# V32F20x_CM33 register map
File version: 1.0.3
CPU: CM33 r0p4, little endian, MPU, FPU, DSP, 3 interrupt priority bits, 8 SAU regions
Registers are 32-bit, read-write, reset 0x0 unless marked. A register's access mark holds for its fields unless they carry their own. Offsets are from the block's base; [hi:lo] are bit positions; {n}, {i} and the like mark numbered series.

## HFM — HFM Peripheral Interface
Base 0x21015000
0x00 DEVID ro reset 0xA0000B0C — HFM device ID register.
  [31:0] DEVID — HFM device ID value.
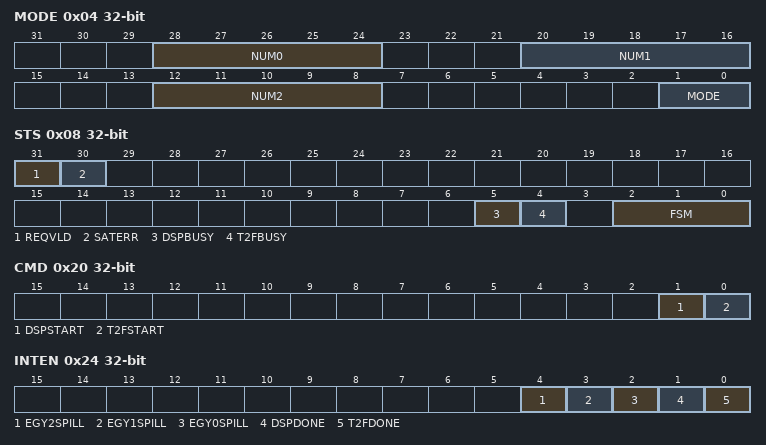
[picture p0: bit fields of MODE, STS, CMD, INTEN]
0x04 MODE — HFM mode configuration register.
  [28:24] NUM0 — Energy 0 bucket Harmonic number selection.
  [20:16] NUM1 — Energy 1 bucket Harmonic number selection.
  [12:8] NUM2 — Energy 2 bucket Harmonic number selection.
  [1:0] MODE — HFM mode configuration.
0x08 STS ro — HFM general status register.
  [31] REQVLD — Valid Request asserted.
  [30] SATERR — Saturation Error Occur.
  [5] DSPBUSY — The DSP is busy.
  [4] T2FBUSY — The T2F is busy.
  [2:0] FSM — FFT Transform state.
0x0C EXCHADDR — FFT exchange buffer base address register.
  [31:0] EXCHADDR — FFT calculation exchange buffer base address.
0x10 WAVEADDR — Waveform buffer base address register.
  [31:0] WAVEADDR — The source waveform FFT Result buffer base address
0x14 DSPINSTRADDR reset 0x80000 — DSP instructions base address register.
  [31:0] INSTRADDR — The DSP instruction buffer base address.
0x18 DSPEXCHADDR — DSP power result and exchange buffer base address register
  [31:0] DSPEXCHADDR — The DSP power value and exchange buffer base address
0x20 CMD — HFM command register.
  [1] DSPSTART — Start the DSP processing.
  [0] T2FSTART — Start run Bit. Write 1 to start the engine.
0x24 INTEN — HFM interrupt enable register.
  [4] EGY2SPILL — ENGY2 spill interrupt enable control.
  [3] EGY1SPILL — ENGY1 spill interrupt enable control.
  [2] EGY0SPILL — ENGY0 spill interrupt enable control.
  [1] DSPDONE — DSP process done interrupt enable control.
  [0] T2FDONE — T2F command done interrupt enable control.
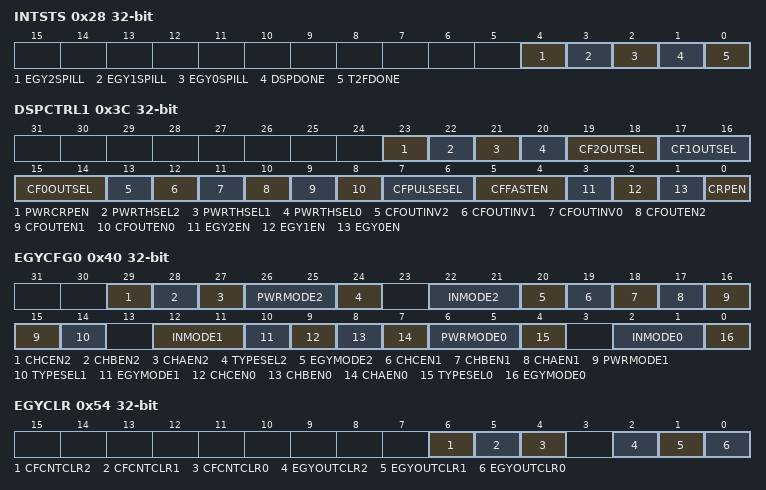
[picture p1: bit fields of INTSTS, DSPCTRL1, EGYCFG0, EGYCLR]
0x28 INTSTS — HFM interrupt status register.
  [4] EGY2SPILL — ENGY2 spill interrupt status.
  [3] EGY1SPILL — ENGY1 spill interrupt status.
  [2] EGY0SPILL — ENGY0 spill interrupt status.
  [1] DSPDONE — DSP process done interrupt status.
  [0] T2FDONE — T2F command done interrupt status.
{0x30+4i} EGY{i}CONST (i=0..2) — Energy x accumulation constant value register.
  [31:0] CONST — Energy bucket 0/1/2 accumulation constant value.
0x3C DSPCTRL1 — DSP control register 1.
  [23] PWRCRPEN — Power creeping enable control.
  [22] PWRTHSEL2 — Energy 2 power threshold value selection.
  [21] PWRTHSEL1 — Energy 1 power threshold value selection.
  [20] PWRTHSEL0 — Energy 0 power threshold value selection.
  [19:18] CF2OUTSEL — CF2 output energy bucket selection.
  [17:16] CF1OUTSEL — CF1 output energy bucket selection.
  [15:14] CF0OUTSEL — CF0 output energy bucket selection.
  [13] CFOUTINV2 — Polarity reversal of Energy Bucket 2.
  [12] CFOUTINV1 — Polarity reversal of Energy Bucket 1.
  [11] CFOUTINV0 — Polarity reversal of Energy Bucket 0.
  [10] CFOUTEN2 — CF2 output enable control.
  [9] CFOUTEN1 — CF1 output enable control.
  [8] CFOUTEN0 — CF0 output enable control.
  [7:6] CFPULSESEL — CF pulse period selection.
  [5:4] CFFASTEN — CF output frequency select through changing the threshold value
  [3] EGY2EN — Energy bucket 2 switch (including CF)
  [2] EGY1EN — Energy bucket 1 switch (including CF)
  [1] EGY0EN — Energy bucket 0 switch (including CF)
  [0] CRPEN — Energy bucket to prevent creeping switch control.
0x40 EGYCFG0 — Energy configuration register 0.
  [29] CHCEN2 — C channel of energy bucket 2 enable control.
  [28] CHBEN2 — B channel of energy bucket 2 enable control.
  [27] CHAEN2 — A channel of energy bucket 2 enable control.
  [26:25] PWRMODE2 — Energy bucket 2 power accumulation mode select
  [24] TYPESEL2 — Energy barrel 2 Power accumulation source selection
  [22:21] INMODE2 — Energy barrel 2 Accumulation source selection.
  [20] EGYMODE2 — Energy barrel 2 Energy accumulation mode selection
  [19] CHCEN1 — C channel of energy bucket 1 enable control.
  [18] CHBEN1 — B channel of energy bucket 1 enable control.
  [17] CHAEN1 — A channel of energy bucket 1 enable control.
  [16:15] PWRMODE1 — Energy bucket 1 power accumulation mode select
  [14] TYPESEL1 — Energy barrel 1 Power accumulation source selection
  [12:11] INMODE1 — Energy barrel 1 Accumulation source selection.
  [10] EGYMODE1 — Energy barrel 1 Energy accumulation mode selection
  [9] CHCEN0 — C channel of energy bucket 0 enable control.
  [8] CHBEN0 — B channel of energy bucket 0 enable control.
  [7] CHAEN0 — A channel of energy bucket 0 enable control.
  [6:5] PWRMODE0 — Energy bucket 0 power accumulation mode select
  [4] TYPESEL0 — Energy barrel 0 Power accumulation source selection
  [2:1] INMODE0 — Energy barrel 0 Accumulation source selection.
  [0] EGYMODE0 — Energy barrel 0 Energy accumulation mode selection
0x44 EGYPRCTH — Prevent potential threshold register.
  [31:0] PRCTH — Prevent creeping threshold
0x48 EGYPWRTH0 — Energy accumulation threshold 0 register.
  [31:0] PWRTH — Energy accumulation threshold 0.
0x4C EGYPWRTH1 — Energy accumulation threshold 1 register.
  [31:0] PWRTH — Energy accumulation threshold 1.
0x50 EGYCFDIVTH — CF frequency division coefficient register.
  [15:0] CFDIVTH — Energy bucket overflow counting threshold
0x54 EGYCLR — Energy value and CF count clear register.
  [6] CFCNTCLR2 — CF pulse count clear for energy bucket 2.
  [5] CFCNTCLR1 — CF pulse count clear for energy bucket 1.
  [4] CFCNTCLR0 — CF pulse count clear for energy bucket 0.
  [2] EGYOUTCLR2 — Cumulative energy value clear for energy bucket 2.
  [1] EGYOUTCLR1 — Cumulative energy value clear for energy bucket 1.
  [0] EGYOUTCLR0 — Cumulative energy value clear for energy bucket 0.
0x5C EGYCLKDIV — Power accumulation frequency register.
  [7:0] CLKDIV — Energy bucket accumulation cycle control.
{0x60+8i} EGY{i}OUTL ro (i=0..2) — Energy bucket x accumulation value low register.
  [31:0] OUTL — Accumulative value of energy bucket 0 1 2 low 32 bits
{0x64+8i} EGY{i}OUTH ro (i=0..2) — Energy bucket x accumulation value high register.
  [13:0] OUTH — Accumulative value of energy bucket 0 1 2 high 14 bits
{0x78+4i} EGY{i}CFCNT ro (i=0..2) — Energy bucket x CF counter register.
  [31:0] CFCNT — Energy bucket 0/1/2, CF pulse count value.
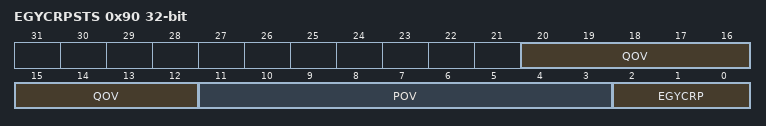
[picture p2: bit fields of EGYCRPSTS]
0x90 EGYCRPSTS ro — Energy creep status register.
  [20:12] QOV — Reactive power creeping status of each channel.
  [11:3] POV — Active power creeping status of each channel.
  [2:0] EGYCRP — The flag of creeping status.
0x94 PWROVTHH — Power creep over high threshold register.
  [31:0] THH — Power creep over high threshold.
0x98 PWROVTHL — Power creep over low threshold register.
  [31:0] THL — Power creep over low threshold.
0xA0 DSPCALICFGADDR reset 0x81700 — DSP PQ/RMS calibration configuration base address register
  [31:0] ADDR — The DSP calibration for PQ RMS base address default is NVR address
0x180 PW_P0_0 — The active power of phase A of energy bucket 0
  [31:0] P0_0 — Power value calculation by DSP
{0x184+0xC*i} PW_P{i}_1 (i=0..2) — The active power of phase B of energy bucket {i}
  [31:0] P{i}_1 — Power value calculation by DSP
{0x188+0xC*i} PW_P{i}_2 (i=0..2) — The active power of phase C of energy bucket {i}
  [31:0] P{i}_2 — Power value calculation by DSP
0x18C PW_P1_0 — The active power of phase A of energy bucket 1
  [31:0] P1_0 — Power value calculation by DSP
0x198 PW_P2_0 wo — The active power of phase A of energy bucket 2
  [31:0] P2_0 — Power value calculation by DSP
{0x1A4+0xC*i} PW_Q{i}_0 (i=0..2) — The reactive power of phase A of energy bucket {i}
  [31:0] Q{i}_0 — Power value calculation by DSP
{0x1A8+0xC*i} PW_Q{i}_1 (i=0..2) — The reactive power of phase B of energy bucket {i}
  [31:0] Q{i}_1 — Power value calculation by DSP
{0x1AC+0xC*i} PW_Q{i}_2 (i=0..2) — The reactive power of phase C of energy bucket {i}
  [31:0] Q{i}_2 — Power value calculation by DSP
{0x1C8+0xC*i} PW_RMS{i}_0 (i=0..2) — The RMS power of phase A of energy bucket {i}
  [31:0] RMS{i}_0 — Power value calculation by DSP
{0x1CC+0xC*i} PW_RMS{i}_1 (i=0..2) — The RMS power of phase B of energy bucket {i}
  [31:0] RMS{i}_1 — Power value calculation by DSP
{0x1D0+0xC*i} PW_RMS{i}_2 (i=0..2) — The RMS power of phase C of energy bucket {i}
  [31:0] RMS{i}_2 — Power value calculation by DSP
